# MMCSD0_SS_CFG register map
Vendor: Texas Instruments
Peripheral module from a debugger description file (folder am243x).
Registers are 32-bit, read-write, reset 0x0 unless marked. A register's access mark holds for its fields unless they carry their own. Offsets are as the file gives them; lines under a group give offsets from that group; [hi:lo] are bit positions; {n}, {i} and the like mark numbered series; 'fields as' and 'values as' point back to an identical list; <NAME> marks a mode.

## MMCSD0_SS_CFG
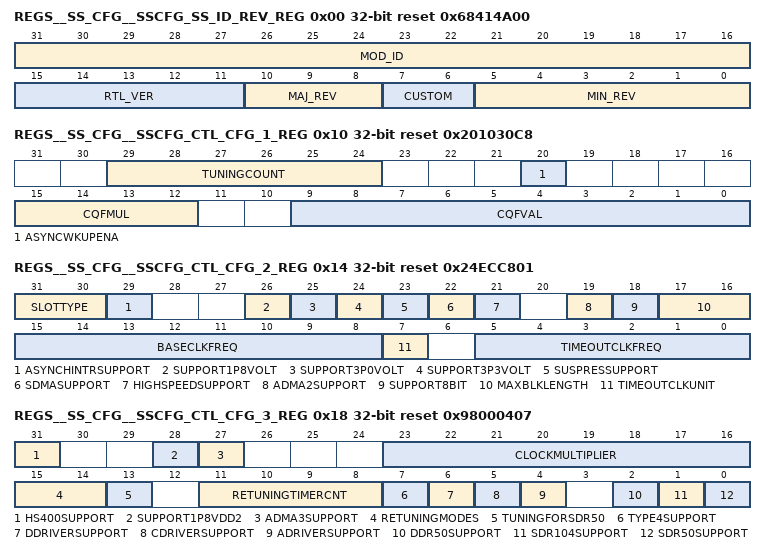
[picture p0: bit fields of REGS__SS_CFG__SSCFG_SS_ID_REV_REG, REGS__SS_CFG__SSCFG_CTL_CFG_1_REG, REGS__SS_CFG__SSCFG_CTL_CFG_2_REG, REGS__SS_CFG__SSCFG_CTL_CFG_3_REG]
0x00 REGS__SS_CFG__SSCFG_SS_ID_REV_REG ro reset 0x68414A00 — The Subsystem ID and Revision Register contains the module ID, major, and minor revisions for the subsystem
  [31:16] MOD_ID — Module ID
  [15:11] RTL_VER — RTL version
  [10:8] MAJ_REV — Major revision
  [7:6] CUSTOM
  [5:0] MIN_REV — Minor revision
0x10 REGS__SS_CFG__SSCFG_CTL_CFG_1_REG reset 0x201030C8 — The Controller Config 1 Register contains various fields to control the configuration ports on the Arasan eMMC/SD Controller. For detailed functionality of the Arasan eMMC/SD Controller configuration ports please refer to its specification listed in Section 1.2.
  [29:24] TUNINGCOUNT — Configures the Number of Taps (Phases) of the RX clock that is supported. The Tuning State machine uses this information to select one of the Taps (Phases) of the RX clock during the Tuning Procedure.
  [20] ASYNCWKUPENA — Determines the Wakeup Signal Generation Mode. 0: Synchronous Wakeup Mode: The xin_clk has to be running for this mode. The Card Insertion/Removal/Interrupt events are detected synchronously on the xin_clk and the Wakeup Event is generated. The Assertion and deassertion of the wakeup Event signal synchronous to xin_clk. 1: Asyncrhonous Wakeup Mode: The xin_clk and the host_clk can be stopped in this mode and the Wake up Event is asynchronously generated based on the Card Insertion/Removal/Interrupt Events. The Assertion and deassertion of the wakeup Event signal is asynchronous.
  [15:12] CQFMUL — FMUL for the CQ Internal Timer Clock Frequency
  [9:0] CQFVAL — FVAL for the CQ Internal Timer Clock Frequency
0x14 REGS__SS_CFG__SSCFG_CTL_CFG_2_REG reset 0x24ECC801 — The Controller Config 2 Register contains various fields to control the configuration ports on the Arasan eMMC/SD Controller. For detailed functionality of the Arasan eMMC/SD Controller configuration ports please refer to its specification listed in Section 1.2. This register sets the lsb fields in the Capabilities Register inside the Arasan eMMC/SD Controller.
  [31:30] SLOTTYPE — Slot Type. Should be set based on the final product usage. 00 - Removable SCard Slot, 01 - Embedded Slot for One Device, 10 - Shared Bus Slot, 11 - Reserved.
  [29] ASYNCHINTRSUPPORT — Asynchronous Interrupt Support. Suggested Value is 1'b1 (The Core supports monitoring of Asynchronous Interrupt).
  [26] SUPPORT1P8VOLT — 1.8V Support. Suggested Value is 1'b1 (The 1.8 Volt Switching is supported by Core). Optionally can be set to 1'b0 if the application doesn't want 1.8V switching (SD3.0).
  [25] SUPPORT3P0VOLT — 3.0V Support. Should be set based on whether 3.0V is supported on the SD Interface.
  [24] SUPPORT3P3VOLT — 3.3V Support. Suggested Value is 1'b1 as the 3.3 V is the default voltage on the SD Interface.
  [23] SUSPRESSUPPORT — Suspend/Resume Support. Suggested Value is 1'b1 (The Suspend/Resume is supported by Core). Optionally can be set to 1'b0 if the application doesn't want to support Suspend/Resume Mode.
  [22] SDMASUPPORT — SDMA Support. Suggested Value is 1'b1 (The SDMA is supported by Core). Optionally can be set to 1'b0 if the application doesn't want to support SDMA Mode.
  [21] HIGHSPEEDSUPPORT — High Speed Support. Suggested Value is 1'b1 (The High Speed mode is supported by Core).
  [19] ADMA2SUPPORT — ADMA2 Support. Suggested Value is 1'b1 (The ADMA2 is supported by Core). Optionally can be set to 1'b0 if the application doesn't want to support ADMA2 Mode.
  [18] SUPPORT8BIT — 8-bit Support for Embedded Device. Suggested Value is 1'b1 (The Core supports 8-bit Interface). Optionally an be set to 1'b0 if the Application supports only 4-bit SD Interface.
  [17:16] MAXBLKLENGTH — Max Block Length. Maximum Block Length supported by the Core/Device. 00: 512 (Bytes), 01: 1024, 10: 2048, 11: Reserved.
  [15:8] BASECLKFREQ — Base Clock Frequency for SD Clock. This is the frequency of the xin_clk.
  [7] TIMEOUTCLKUNIT — Timeout Clock Unit. Suggested Value is 1'b0 (KHz).
  [5:0] TIMEOUTCLKFREQ — Timeout Clock Frequency. Suggested Value is 1 KHz. Internally the 1msec Timer is used for Timeout Detection. The 1msec Timer is generated from the xin_clk.
0x18 REGS__SS_CFG__SSCFG_CTL_CFG_3_REG reset 0x98000407 — The Controller Config 3 Register contains various fields to control the configuration ports on the Arasan eMMC/SD Controller. For detailed functionality of the Arasan eMMC/SD Controller configuration ports please refer to its specification listed in Section 1.2. This register sets the msb fields in the Capabilities Register inside the Arasan eMMC/SD Controller.
  [31] HS400SUPPORT — HS400 Support. Suggested Value is 1'b1 (The Core supports HS400 Mode). This applies only to eMMC5.0 mode. This should be set to 1'b0 for SD3.0 mode Optionally can be set to 1'b0 if the application doesn't want to support HS400.
  [28] SUPPORT1P8VDD2 — 1.8V VDD2 Support.
  [27] ADMA3SUPPORT
  [23:16] CLOCKMULTIPLIER — Clock Multiplier. This field indicates clock multiplier value of programmable clock generator. Refer to Clock Control register. Setting 00h means that Host Controller does not support programmable clock generator. FFh Clock Multiplier M = 256, ...., 02h Clock Multiplier M = 3, 01h Clock Multiplier M = 2, 00h Clock Multiplier is Not Supported.
  [15:14] RETUNINGMODES — Re-Tuning Modes. Should be set to 2'b00 as the Core supports only the Software Timer based Re-Tuning.
  [13] TUNINGFORSDR50 — Use Tuning for SDR50. This bit should be set if the Application wants Tuning be used for SDR50 Modes. The Core operates with or with out tuning for SDR50 mode as long as the Clock can be manually tuned using tap delay.
  [11:8] RETUNINGTIMERCNT — Timer Count for Re-Tuning. This is the Timer Count for Re-Tuning Timer for Re-Tuning Mode 1 to 3. Setting to 4'b0 disables Re-Tuning Timer.
  [7] TYPE4SUPPORT — Driver Type 4 Support. This bit should be set based on whether Driver Type 4 for 1.8 Signalling is supported or not.
  [6] DDRIVERSUPPORT — Driver Type D Support. This bit should be set based on whether Driver Type D for 1.8 Signalling is supported or not.
  [5] CDRIVERSUPPORT — Driver Type C Support. This bit should be set based on whether Driver Type C for 1.8 Signalling is supported or not.
  [4] ADRIVERSUPPORT — Driver Type A Support. This bit should be set based on whether Driver Type A for 1.8 Signalling is supported or not.
  [2] DDR50SUPPORT — DDR50 Support. Suggested Value is 1'b1 (The Core supports DDR50 mode of operation). Optionally can be set to 1'b0 if the application doesn't want to support DDR50.
  [1] SDR104SUPPORT — SDR104 Support. Suggested Value is 1'b1 (The Core supports SDR104 mode of operation). Optionally can be set to 1'b0 if the application doesn't want to support SDR104.
  [0] SDR50SUPPORT — SDR50 Support. Suggested Value is 1'b1 (The Core supports SDR50 mode of operation). Optionally can be set to 1'b0 if the application doesn't want to support SDR50.
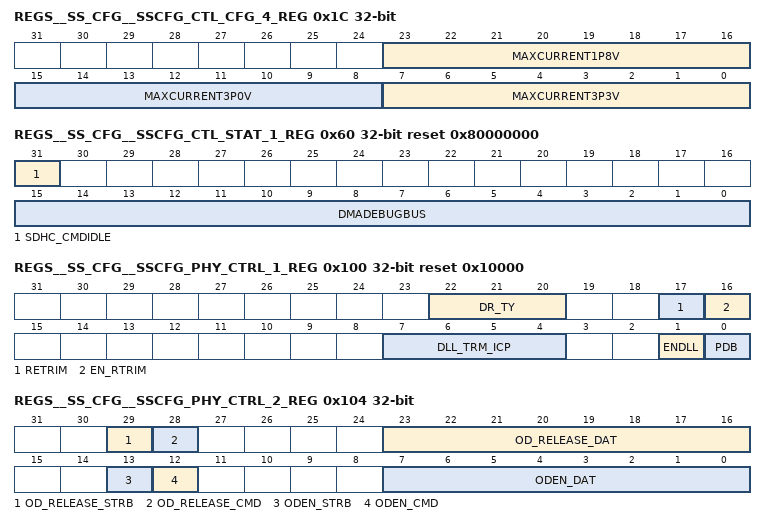
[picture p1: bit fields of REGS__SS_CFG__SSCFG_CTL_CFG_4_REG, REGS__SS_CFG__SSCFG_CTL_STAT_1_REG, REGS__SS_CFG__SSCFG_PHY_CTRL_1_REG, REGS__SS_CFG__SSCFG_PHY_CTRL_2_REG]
0x1C REGS__SS_CFG__SSCFG_CTL_CFG_4_REG — The Controller Config 4 Register contains various fields to control the configuration ports on the Arasan eMMC/SD Controller. For detailed functionality of the Arasan eMMC/SD Controller configuration ports please refer to its specification listed in Section 1.2. This register sets the lsb fields in the Maximum Current Capabilities Register inside the Arasan eMMC/SD Controller.
  [23:16] MAXCURRENT1P8V — Maximum Current for 1.8V.
  [15:8] MAXCURRENT3P0V — Maximum Current for 3.0V.
  [7:0] MAXCURRENT3P3V — Maximum Current for 3.3V.
0x20 REGS__SS_CFG__SSCFG_CTL_CFG_5_REG — The Controller Config 5 Register contains various fields to control the configuration ports on the Arasan eMMC/SD Controller. For detailed functionality of the Arasan eMMC/SD Controller configuration ports please refer to its specification listed in Section 1.2. This register sets the msb fields in the Maximum Current Capabilities Register inside the Arasan eMMC/SD Controller.
  [7:0] MAXCURRENTVDD2 — Maximum Current for 1.8 V (VDD2).
0x24 REGS__SS_CFG__SSCFG_CTL_CFG_6_REG reset 0x100 — The Controller Config 6 Register contains various fields to control the configuration ports on the Arasan eMMC/SD Controller. For detailed functionality of the Arasan eMMC/SD Controller configuration ports please refer to its specification listed in Section 1.2. This register sets the fields in the Preset Values Register for Initialization inside the Arasan eMMC/SD Controller.
  [12:0] INITPRESETVAL — Preset Value for Initialization.
0x28 REGS__SS_CFG__SSCFG_CTL_CFG_7_REG reset 0x4 — The Controller Config 7 Register contains various fields to control the configuration ports on the Arasan eMMC/SD Controller. For detailed functionality of the Arasan eMMC/SD Controller configuration ports please refer to its specification listed in Section 1.2. This register sets the fields in the Preset Values Register for Default Speed inside the Arasan eMMC/SD Controller.
  [12:0] DSPDPRESETVAL — Preset Value for Default Speed.
0x2C REGS__SS_CFG__SSCFG_CTL_CFG_8_REG reset 0x2 — The Controller Config 8 Register contains various fields to control the configuration ports on the Arasan eMMC/SD Controller. For detailed functionality of the Arasan eMMC/SD Controller configuration ports please refer to its specification listed in Section 1.2. This register sets the fields in the Preset Values Register for High Speed inside the Arasan eMMC/SD Controller.
  [12:0] HSPDPRESETVAL — Preset Value for High Speed.
0x30 REGS__SS_CFG__SSCFG_CTL_CFG_9_REG reset 0x4 — The Controller Config 9 Register contains various fields to control the configuration ports on the Arasan eMMC/SD Controller. For detailed functionality of the Arasan eMMC/SD Controller configuration ports please refer to its specification listed in Section 1.2. This register sets the fields in the Preset Values Register for SDR12 inside the Arasan eMMC/SD Controller.
  [12:0] SDR12PRESETVAL — Preset Value for SDR12.
0x34 REGS__SS_CFG__SSCFG_CTL_CFG_10_REG reset 0x2 — The Controller Config 10 Register contains various fields to control the configuration ports on the Arasan eMMC/SD Controller. For detailed functionality of the Arasan eMMC/SD Controller configuration ports please refer to its specification listed in Section 1.2. This register sets the fields in the Preset Values Register for SDR25 inside the Arasan eMMC/SD Controller.
  [12:0] SDR25PRESETVAL — Preset Value for SDR25.
0x38 REGS__SS_CFG__SSCFG_CTL_CFG_11_REG reset 0x1 — The Controller Config 11 Register contains various fields to control the configuration ports on the Arasan eMMC/SD Controller. For detailed functionality of the Arasan eMMC/SD Controller configuration ports please refer to its specification listed in Section 1.2. This register sets the fields in the Preset Values Register for SDR50 inside the Arasan eMMC/SD Controller.
  [12:0] SDR50PRESETVAL — Preset Value for SDR50.
0x3C REGS__SS_CFG__SSCFG_CTL_CFG_12_REG — The Controller Config 12 Register contains various fields to control the configuration ports on the Arasan eMMC/SD Controller. For detailed functionality of the Arasan eMMC/SD Controller configuration ports please refer to its specification listed in Section 1.2. This register sets the fields in the Preset Values Register for SDR104 inside the Arasan eMMC/SD Controller.
  [12:0] SDR104PRESETVAL — Preset Value for SDR104.
0x40 REGS__SS_CFG__SSCFG_CTL_CFG_13_REG reset 0x2 — The Controller Config 13 Register contains various fields to control the configuration ports on the Arasan eMMC/SD Controller. For detailed functionality of the Arasan eMMC/SD Controller configuration ports please refer to its specification listed in Section 1.2. This register sets the fields in the Preset Values Register for DDR50 inside the Arasan eMMC/SD Controller.
  [12:0] DDR50PRESETVAL — Preset Value for DDR50.
0x44 REGS__SS_CFG__SSCFG_CTL_CFG_14_REG reset 0x1 — The Controller Config 14 Register contains various fields to control the configuration ports on the Arasan eMMC/SD Controller. For detailed functionality of the Arasan eMMC/SD Controller configuration ports please refer to its specification listed in Section 1.2. This register sets the fields in the Preset Values Register for HS400 inside the Arasan eMMC/SD Controller.
  [12:0] HS400PRESETVAL — Preset Value for HS400.
0x60 REGS__SS_CFG__SSCFG_CTL_STAT_1_REG ro reset 0x80000000 — The Controller Status 1 Register contains various fields to reflect the status of the debug ports on the Arasan eMMC/SD Controller. For detailed functionality of the Arasan eMMC/SD Controller debug ports please refer to its specification listed in Section 1.2.
  [31] SDHC_CMDIDLE — Idle signal to enable S/W to gate off the clocks.
  [15:0] DMADEBUGBUS — DMA_CTRL Debug Bus.
0x64 REGS__SS_CFG__SSCFG_CTL_STAT_2_REG ro reset 0x10 — The Controller Status 2 Register contains various fields to reflect the status of the debug ports on the Arasan eMMC/SD Controller. For detailed functionality of the Arasan eMMC/SD Controller debug ports please refer to its specification listed in Section 1.2.
  [15:0] CMDDEBUGBUS — CMD_CTRL Debug Bus.
0x68 REGS__SS_CFG__SSCFG_CTL_STAT_3_REG ro — The Controller Status 3 Register contains various fields to reflect the status of the debug ports on the Arasan eMMC/SD Controller. For detailed functionality of the Arasan eMMC/SD Controller debug ports please refer to its specification listed in Section 1.2.
  [15:0] TXDDEBUGBUS — TXD_CTRL Debug Bus.
0x6C REGS__SS_CFG__SSCFG_CTL_STAT_4_REG ro — The Controller Status 4 Register contains various fields to reflect the status of the debug ports on the Arasan eMMC/SD Controller. For detailed functionality of the Arasan eMMC/SD Controller debug ports please refer to its specification listed in Section 1.2.
  [15:0] RXDDEBUGBUS0 — RXD_CTRL Debug Bus (SD CLK).
0x70 REGS__SS_CFG__SSCFG_CTL_STAT_5_REG ro reset 0x8 — The Controller Status 5 Register contains various fields to reflect the status of the debug ports on the Arasan eMMC/SD Controller. For detailed functionality of the Arasan eMMC/SD Controller debug ports please refer to its specification listed in Section 1.2.
  [15:0] RXDDEBUGBUS1 — RXD_CTRL Debug Bus (RX CLK).
0x74 REGS__SS_CFG__SSCFG_CTL_STAT_6_REG ro — The Controller Status 6 Register contains various fields to reflect the status of the debug ports on the Arasan eMMC/SD Controller. For detailed functionality of the Arasan eMMC/SD Controller debug ports please refer to its specification listed in Section 1.2.
  [15:0] TUNDEBUGBUS — TUN_CTRL Debug Bus.
0x100 REGS__SS_CFG__SSCFG_PHY_CTRL_1_REG reset 0x10000 — The PHY Control 1 Register contains various fields to control the ports on the Arasan eMMC/SD PHY. For detailed functionality of the Arasan eMMC/SD PHY control ports please refer to its specification listed in Section 1.2.
  [22:20] DR_TY — Drive Source/Sink impedance programming. 0 => 50 Ohms, 1 => 33 Ohms, 2 => 66 Ohms, 3 => 100 Ohms, 4 => 40 Ohms.
  [17] RETRIM — Start CALIO calibration cycle. At positive edge initiates CALIO calibration cycle.
  [16] EN_RTRIM — CALIO enable. Enables CALIO, If enabled CALIO will start calibration cycle at phyctrl_pdb positive edge.
  [7:4] DLL_TRM_ICP — Analog DLL's Charge Pump Current Trim. Programs the analog DLL loop gain.
  [1] ENDLL — Enable DLL. Enables the analog DLL circuits.
  [0] PDB — CALIO S/M power down bar. SOC asserts after power up sequence is completed.
0x104 REGS__SS_CFG__SSCFG_PHY_CTRL_2_REG — The PHY Control 2 Register contains various fields to control the ports on the Arasan eMMC/SD PHY. For detailed functionality of the Arasan eMMC/SD PHY control ports please refer to its specification listed in Section 1.2.
  [29] OD_RELEASE_STRB — Disable an internal 4.7K pull up resistor on STRB line in open drain mode.
  [28] OD_RELEASE_CMD — Disable an internal 4.7K pull up resistor on CMD line in open drain mode.
  [23:16] OD_RELEASE_DAT — Disable an internal 4.7K pull up resistor on data lines in open drain mode.
  [13] ODEN_STRB — Open Drain Enable on STRB line.
  [12] ODEN_CMD — Open Drain Enable on CMD line.
  [7:0] ODEN_DAT — Open Drain Enable on DAT lines.
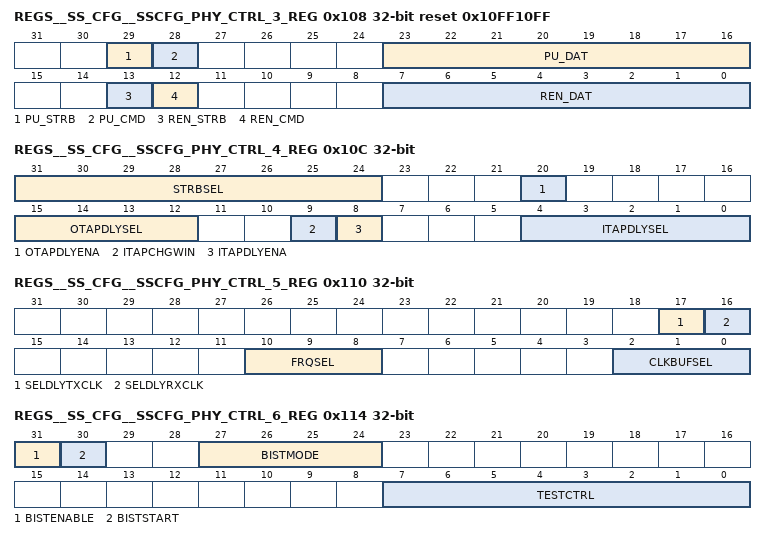
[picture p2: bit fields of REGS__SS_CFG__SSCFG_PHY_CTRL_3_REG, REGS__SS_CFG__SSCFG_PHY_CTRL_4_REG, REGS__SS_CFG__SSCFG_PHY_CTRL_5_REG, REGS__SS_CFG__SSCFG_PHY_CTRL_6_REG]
0x108 REGS__SS_CFG__SSCFG_PHY_CTRL_3_REG reset 0x10FF10FF — The PHY Control 3 Register contains various fields to control the ports on the Arasan eMMC/SD PHY. For detailed functionality of the Arasan eMMC/SD PHY control ports please refer to its specification listed in Section 1.2.
  [29] PU_STRB — Enable pull up on STRB line. If ren_strb is high week pull up is enabled on STRB line.
  [28] PU_CMD — Enable pull up on CMD line. If ren_cmd is high week pull up is enabled on CMD line.
  [23:16] PU_DAT — Enable pull up on DAT lines. If ren_dat is high week pull up is enabled on DATA lines.
  [13] REN_STRB — Enable pull up/down on the STRB line. If pu_strb is high a week pull up is enabled on STRB line, if low week pull down is enabled on STRB line.
  [12] REN_CMD — Enable pull up/down on the CMD line. If pu_cmd is high a week pull up is enabled on CMD line, if low week pull down is enabled on CMD line.
  [7:0] REN_DAT — Enable pull up/down on the DAT lines. If pu_dat is high a week pull up is enabled on DATA lines, if low week pull down is enabled on DATA lines.
0x10C REGS__SS_CFG__SSCFG_PHY_CTRL_4_REG — The PHY Control 4 Register contains various fields to control the ports on the Arasan eMMC/SD PHY. For detailed functionality of the Arasan eMMC/SD PHY control ports please refer to its specification listed in Section 1.2.
  [31:24] STRBSEL — Select the Four Taps for each of STRB_90 and STRB_180 Outputs. strbsel[3:2] selects one of the four for STRB_180 and strbsel[1:0] selects the four taps for STRB_90.
  [20] OTAPDLYENA — Output Tap Delay Enable. Enables manual control of the TX clock tap delay, for clocking the final stage flops for maintaining Hold requirements on EMMC Interface.
  [15:12] OTAPDLYSEL — Output Tap Delay Select. Manual control of the TX clock tap delay for clocking the final stage flops for maintaining Hold requirements on EMMC Interface.
  [9] ITAPCHGWIN — Input Tap Change Window. It gets asserted by the controller while changing the itapdlysel. Used to gate of the RX clock during switching the clock source while tap is changing to avoid clock glitches.
  [8] ITAPDLYENA — Input Tap Delay Enable. This is used for the manual control of the RX clock Tap Delay in non HS200/HS400 modes.
  [4:0] ITAPDLYSEL — Input Tap Delay Select. Manual control of the RX clock Tap Delay in the non HS200/HS400 modes.
0x110 REGS__SS_CFG__SSCFG_PHY_CTRL_5_REG — The PHY Control 5 Register contains various fields to control the ports on the Arasan eMMC/SD PHY. For detailed functionality of the Arasan eMMC/SD PHY control ports please refer to its specification listed in Section 1.2.
  [17] SELDLYTXCLK — Select the Delay chain based txclk. Enables the TX clock based delay chain rather than analog DLL based delay chain.
  [16] SELDLYRXCLK — Select the Delay chain based rxclk. Enables the RX clock based delay chain rather than analog DLL based delay chain.
  [10:8] FRQSEL — Select the frequency range of DLL operation: 0 => 200MHz to 170 MHz, 1 => 170MHz to 140 MHz, 2 => 140MHz to 110 MHz, 3 => 110MHz to 80MHz, 4 => 80MHz to 50 MHz, 5 => 275Mhz to 250MHz, 6 => 250MHz to 225MHz, 7 => 225MHz to 200MHz.
  [2:0] CLKBUFSEL — Clock Delay Buffer Select. Selects one of the eight taps in the CLK Delay Buffer based on PVT variation.
0x114 REGS__SS_CFG__SSCFG_PHY_CTRL_6_REG — The PHY Control 6 Register contains various fields to control the ports on the Arasan eMMC/SD PHY. For detailed functionality of the Arasan eMMC/SD PHY control ports please refer to its specification listed in Section 1.2.
  [31] BISTENABLE — Internal BIST operation enable. Enables the embedded BIST.
  [30] BISTSTART — Internal BIST start. Starts the embedded BIST operation.
  [27:24] BISTMODE — Internal BIST mode Select. Select the embedded BIST mode of operation.
  [7:0] TESTCTRL — PHY test control: 8'b00010000 => Test EMMC IOs sink impedance, 8'b00010001 => Test EMMC IOs source impedance, 8'b00100000 => Test RX clock phases on data lines, 8'b00110000 => Test TX clock phases on data lines, 8'b01000000 => Test STRB clock phases on data lines.
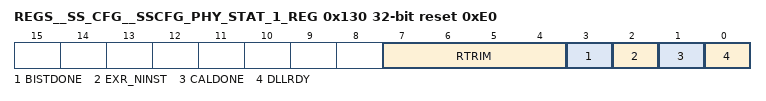
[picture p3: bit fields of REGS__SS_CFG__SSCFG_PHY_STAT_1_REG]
0x130 REGS__SS_CFG__SSCFG_PHY_STAT_1_REG ro reset 0xE0 — The PHY Status 1 Register contains various fields to reflect the status of the Arasan eMMC/SD PHY ports. For detailed functionality of the Arasan eMMC/SD PHY status ports please refer to its specification listed in Section 1.2.
  [7:4] RTRIM — CALIO Calibration Result. Holds the content of CALIO Impedance Calibration Result.
  [3] BISTDONE — Internal BIST completed test cycle. Indicates that the embedded BIST has completed the test cycle.
  [2] EXR_NINST — External Resistor on CALIO absent. Indicates trim cycle started and external resistor is absent.
  [1] CALDONE — STATUS, indicate that CALIO Calibration is completed successfully.
  [0] DLLRDY — DLL ready. Indicates that DLL loop is locked.
0x134 REGS__SS_CFG__SSCFG_PHY_STAT_2_REG ro — The PHY Status 2 Register contains various fields to reflect the status of the Arasan eMMC/SD PHY ports. For detailed functionality of the Arasan eMMC/SD PHY status ports please refer to its specification listed in Section 1.2.
  [31:0] BISTSTATUS — Internal BIST data compare results. BIST cycle data comparison results.
